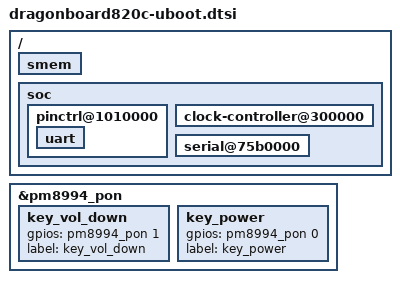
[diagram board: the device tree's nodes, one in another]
// SPDX-License-Identifier: GPL-2.0+
/*
 * U-Boot addition to handle Dragonboard 820c pins
 *
 * (C) Copyright 2017 Jorge Ramirez-Ortiz <jorge.ramirez-ortiz@linaro.org>
 */

/ {
	smem {
		u-boot,dm-all;
	};

	soc {
		u-boot,dm-all;

		pinctrl@1010000 {
			u-boot,dm-all;

			uart {
				u-boot,dm-all;
			};
		};

		clock-controller@300000 {
			u-boot,dm-all;
		};

		serial@75b0000 {
			u-boot,dm-all;
		};
	};
};

&pm8994_pon {
	key_vol_down {
		gpios = <&pm8994_pon 1 0>;
		label = "key_vol_down";
	};

	key_power {
		gpios = <&pm8994_pon 0 0>;
		label = "key_power";
	};
};
